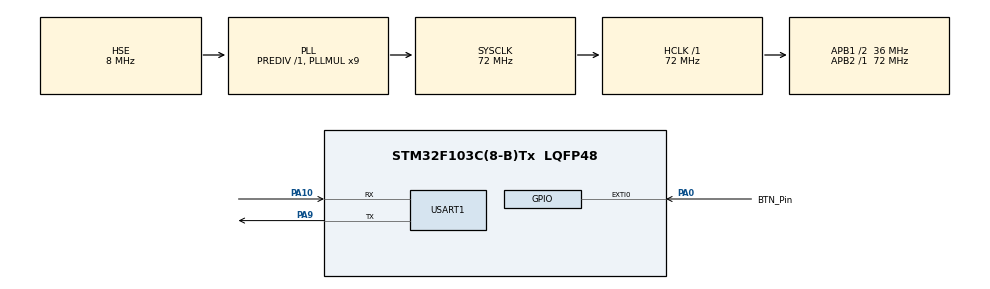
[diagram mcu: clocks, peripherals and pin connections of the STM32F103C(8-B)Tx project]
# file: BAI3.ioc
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Dma.Request0=USART1_TX
Dma.USART1_TX.0.Direction=DMA_MEMORY_TO_PERIPH
Dma.USART1_TX.0.Instance=DMA1_Channel4
Dma.USART1_TX.0.MemDataAlignment=DMA_MDATAALIGN_BYTE
Dma.USART1_TX.0.MemInc=DMA_MINC_ENABLE
Dma.USART1_TX.0.Mode=DMA_NORMAL
Dma.USART1_TX.0.PeriphDataAlignment=DMA_PDATAALIGN_BYTE
Dma.USART1_TX.0.PeriphInc=DMA_PINC_DISABLE
Dma.USART1_TX.0.Priority=DMA_PRIORITY_LOW
Mcu.Family=STM32F1
Mcu.Name=STM32F103C(8-B)Tx
Mcu.Package=LQFP48
NVIC.DMA1_Channel4_IRQn=true\:0\:0\:false\:false\:true\:false\:true\:true
NVIC.EXTI0_IRQn=true\:2\:0\:true\:false\:true\:true\:true\:true
NVIC.PriorityGroup=NVIC_PRIORITYGROUP_4
NVIC.USART1_IRQn=true\:1\:0\:true\:false\:true\:false\:true\:true
PA0-WKUP.GPIO_Label=BTN_Pin
PA0-WKUP.GPIO_ModeDefaultEXTI=GPIO_MODE_IT_FALLING
PA0-WKUP.GPIO_PuPd=GPIO_PULLUP
PA0-WKUP.Signal=GPXTI0
PA10.Mode=Asynchronous
PA10.Signal=USART1_RX
PA13.Mode=Serial_Wire
PA13.Signal=SYS_JTMS-SWDIO
PA14.Mode=Serial_Wire
PA14.Signal=SYS_JTCK-SWCLK
PA9.Mode=Asynchronous
PA9.Signal=USART1_TX
PD0-OSC_IN.Mode=HSE-External-Oscillator
PD0-OSC_IN.Signal=RCC_OSC_IN
PD1-OSC_OUT.Mode=HSE-External-Oscillator
PD1-OSC_OUT.Signal=RCC_OSC_OUT
ProjectManager.HeapSize=0x200
ProjectManager.StackSize=0x400
ProjectManager.TargetToolchain=Makefile
RCC.AHBFreq_Value=72000000
RCC.APB1CLKDivider=RCC_HCLK_DIV2
RCC.APB1Freq_Value=36000000
RCC.APB1TimFreq_Value=72000000
RCC.APB2Freq_Value=72000000
RCC.APB2TimFreq_Value=72000000
RCC.HCLKFreq_Value=72000000
RCC.PLLMUL=RCC_PLL_MUL9
RCC.PLLSourceVirtual=RCC_PLLSOURCE_HSE
RCC.SYSCLKFreq_VALUE=72000000
RCC.SYSCLKSource=RCC_SYSCLKSOURCE_PLLCLK
RCC.USBFreq_Value=72000000
USART1.VirtualMode=VM_ASYNC
board=custom

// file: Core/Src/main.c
/* USER CODE BEGIN Header */
/**
  ******************************************************************************
  * @file           : main.c
  * @brief          : Main program body
  ******************************************************************************
  * @attention
  *
  * Copyright (c) 2026 STMicroelectronics.
  * All rights reserved.
  *
  * This software is licensed under terms that can be found in the LICENSE file
  * in the root directory of this software component.
  * If no LICENSE file comes with this software, it is provided AS-IS.
  *
  ******************************************************************************
  */
/* USER CODE END Header */
#include "main.h"

/* USER CODE BEGIN Includes */
#include <stdio.h>
#include <string.h>
/* USER CODE END Includes */

/* USER CODE BEGIN PTD */
#define BTN_Pin           BTN_Pin_Pin

#define ID_LOP            "D23HTN-01"
#define ID_NHOM           "02"

volatile uint32_t btn_press_count = 0; // Biến đếm số lần nhấn nút
char uart_tx_buffer[64];               // Buffer lưu bản tin truyền DMA
volatile uint8_t uart_dma_busy = 0;
/* USER CODE END PTD */

UART_HandleTypeDef huart1;
DMA_HandleTypeDef hdma_usart1_tx;

void SystemClock_Config(void);
static void MX_GPIO_Init(void);
static void MX_DMA_Init(void);
static void MX_USART1_UART_Init(void);

int main(void)
{

  /* MCU Configuration--------------------------------------------------------*/

  /* Reset of all peripherals, Initializes the Flash interface and the Systick. */
  HAL_Init();

  /* Configure the system clock */
  SystemClock_Config();

  /* Initialize all configured peripherals */
  MX_GPIO_Init();
  MX_DMA_Init();
  MX_USART1_UART_Init();

  /* Infinite loop */
  while (1)
  {

  }
}

void SystemClock_Config(void)
{
  RCC_OscInitTypeDef RCC_OscInitStruct = {0};
  RCC_ClkInitTypeDef RCC_ClkInitStruct = {0};

  /** Initializes the RCC Oscillators according to the specified parameters
  * in the RCC_OscInitTypeDef structure.
  */
  RCC_OscInitStruct.OscillatorType = RCC_OSCILLATORTYPE_HSE;
  RCC_OscInitStruct.HSEState = RCC_HSE_ON;
  RCC_OscInitStruct.HSEPredivValue = RCC_HSE_PREDIV_DIV1;
  RCC_OscInitStruct.HSIState = RCC_HSI_ON;
  RCC_OscInitStruct.PLL.PLLState = RCC_PLL_ON;
  RCC_OscInitStruct.PLL.PLLSource = RCC_PLLSOURCE_HSE;
  RCC_OscInitStruct.PLL.PLLMUL = RCC_PLL_MUL9;
  if (HAL_RCC_OscConfig(&RCC_OscInitStruct) != HAL_OK)
  {
    Error_Handler();
  }

  /** Initializes the CPU, AHB and APB buses clocks
  */
  RCC_ClkInitStruct.ClockType = RCC_CLOCKTYPE_HCLK|RCC_CLOCKTYPE_SYSCLK
                              |RCC_CLOCKTYPE_PCLK1|RCC_CLOCKTYPE_PCLK2;
  RCC_ClkInitStruct.SYSCLKSource = RCC_SYSCLKSOURCE_PLLCLK;
  RCC_ClkInitStruct.AHBCLKDivider = RCC_SYSCLK_DIV1;
  RCC_ClkInitStruct.APB1CLKDivider = RCC_HCLK_DIV2;
  RCC_ClkInitStruct.APB2CLKDivider = RCC_HCLK_DIV1;

  if (HAL_RCC_ClockConfig(&RCC_ClkInitStruct, FLASH_LATENCY_2) != HAL_OK)
  {
    Error_Handler();
  }
}

static void MX_USART1_UART_Init(void)
{

  huart1.Instance = USART1;
  huart1.Init.BaudRate = 115200;
  huart1.Init.WordLength = UART_WORDLENGTH_8B;
  huart1.Init.StopBits = UART_STOPBITS_1;
  huart1.Init.Parity = UART_PARITY_NONE;
  huart1.Init.Mode = UART_MODE_TX_RX;
  huart1.Init.HwFlowCtl = UART_HWCONTROL_NONE;
  huart1.Init.OverSampling = UART_OVERSAMPLING_16;
  if (HAL_UART_Init(&huart1) != HAL_OK)
  {
    Error_Handler();
  }

}

static void MX_DMA_Init(void)
{

  /* DMA controller clock enable */
  __HAL_RCC_DMA1_CLK_ENABLE();

  /* DMA interrupt init */
  /* DMA1_Channel4_IRQn interrupt configuration */
  HAL_NVIC_SetPriority(DMA1_Channel4_IRQn, 0, 0);
  HAL_NVIC_EnableIRQ(DMA1_Channel4_IRQn);

}

static void MX_GPIO_Init(void)
{
  GPIO_InitTypeDef GPIO_InitStruct = {0};

  /* GPIO Ports Clock Enable */
  __HAL_RCC_GPIOD_CLK_ENABLE();
  __HAL_RCC_GPIOA_CLK_ENABLE();

  /*Configure GPIO pin : BTN_Pin_Pin */
  GPIO_InitStruct.Pin = BTN_Pin_Pin;
  GPIO_InitStruct.Mode = GPIO_MODE_IT_FALLING;
  GPIO_InitStruct.Pull = GPIO_PULLUP;
  HAL_GPIO_Init(BTN_Pin_GPIO_Port, &GPIO_InitStruct);

  /* EXTI interrupt init*/
  HAL_NVIC_SetPriority(EXTI0_IRQn, 2, 0);
  HAL_NVIC_EnableIRQ(EXTI0_IRQn);

}

/* USER CODE BEGIN 4 */
void HAL_GPIO_EXTI_Callback(uint16_t GPIO_Pin)
{
    if (GPIO_Pin == BTN_Pin)
    {
        // Chống rung phím đơn giản (debounce) bằng thời gian tick
        static uint32_t last_press_tick = 0;
        if (HAL_GetTick() - last_press_tick > 200)
        {
            last_press_tick = HAL_GetTick();
            btn_press_count++; // Tăng giá trị nút nhấn

            // Nếu DMA không bận, thực hiện gửi bản tin ngay
            if (!uart_dma_busy)
            {
                // Định dạng chuỗi: <ID-Lớp><ID-Nhóm>:BTN:<Giá trị nút nhấn>\n\r
                int len = snprintf(uart_tx_buffer, sizeof(uart_tx_buffer),
                                   "%s%s:BTN:%lu\n\r",
                                   ID_LOP, ID_NHOM, btn_press_count);

                uart_dma_busy = 1; // Khóa lại, đánh dấu DMA đang bận

                // Gửi qua DMA (hàm trả về ngay, không chặn CPU)
                HAL_UART_Transmit_DMA(&huart1, (uint8_t *)uart_tx_buffer, len);
            }
        }
    }
}

// Callback tự động gọi khi DMA truyền xong hết dữ liệu ra UART
void HAL_UART_TxCpltCallback(UART_HandleTypeDef *huart)
{
    if (huart->Instance == USART1)
    {
        uart_dma_busy = 0; // Mở khóa cờ bận để lần bấm sau có thể gửi tiếp
    }
}
/* USER CODE END 4 */

void Error_Handler(void)
{
  __disable_irq();
  while (1)
  {
  }
}
